VERSION " Generated by blabla"

NS_ :

BS_:

BU_: TCU VEHICLE

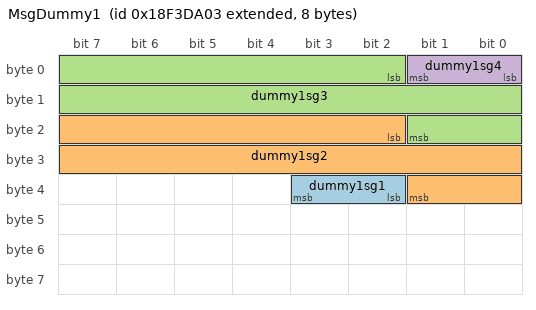
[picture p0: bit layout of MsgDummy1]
BO_ 2566117891 MsgDummy1: 8 Vector__XXX
 SG_ dummy1sg1 : 34|2@1+ (1,0) [0|3] "kkk" Vector__XXX
 SG_ dummy1sg2 : 18|16@1- (1,0) [0|65535] "" Vector__XXX
 SG_ dummy1sg3 : 2|16@1+ (1,0) [0|65535] "" Vector__XXX
 SG_ dummy1sg4 : 0|2@1+ (1,0) [0|3] "" Vector__XXX

BO_ 2565921559 MsgDummy2: 8 Vector__XXX
 SG_ gps_longitude : 39|32@0- (1E-007,0) [-214.7483648|214.7483647] "deg" Vector__XXX
 SG_ gps_latitude : 7|32@0- (1E-007,0) [-214.7483648|214.7483647] "deg" Vector__XXX

BO_ 2565986819 MsgDummy3: 8 TCU
 SG_ dummy3sg1 : 16|16@1+ (0.125,0) [0|8191.875] "" Vector__XXX
